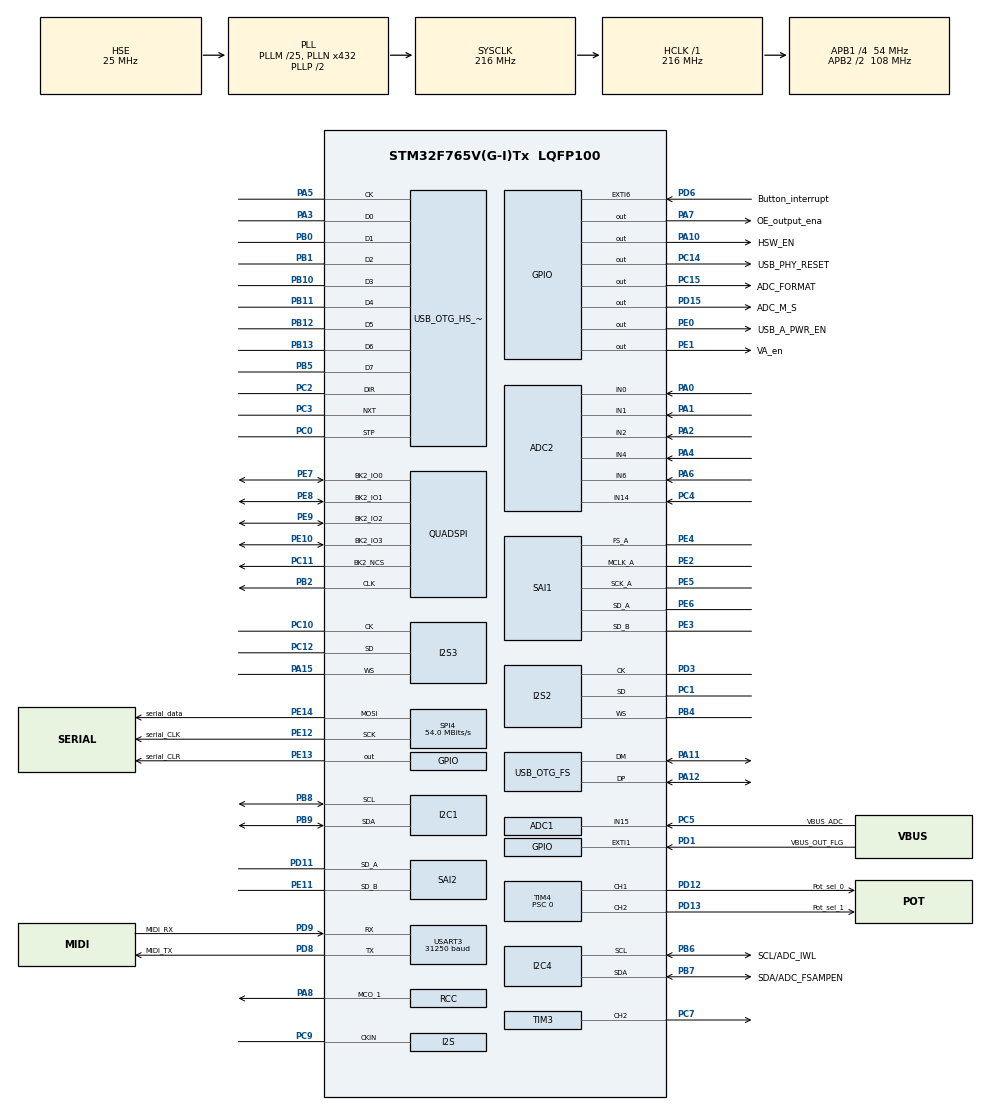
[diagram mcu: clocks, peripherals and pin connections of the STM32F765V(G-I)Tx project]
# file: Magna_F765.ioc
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ADC1.Channel-1\#ChannelRegularConversion=ADC_CHANNEL_TEMPSENSOR
ADC1.Channel-10\#ChannelRegularConversion=ADC_CHANNEL_15
ADC1.Channel-11\#ChannelRegularConversion=ADC_CHANNEL_15
ADC1.Channel-12\#ChannelRegularConversion=ADC_CHANNEL_15
ADC1.Channel-2\#ChannelRegularConversion=ADC_CHANNEL_TEMPSENSOR
ADC1.Channel-3\#ChannelRegularConversion=ADC_CHANNEL_TEMPSENSOR
ADC1.Channel-4\#ChannelRegularConversion=ADC_CHANNEL_TEMPSENSOR
ADC1.Channel-5\#ChannelRegularConversion=ADC_CHANNEL_VREFINT
ADC1.Channel-6\#ChannelRegularConversion=ADC_CHANNEL_VREFINT
ADC1.Channel-7\#ChannelRegularConversion=ADC_CHANNEL_VREFINT
ADC1.Channel-8\#ChannelRegularConversion=ADC_CHANNEL_VREFINT
ADC1.Channel-9\#ChannelRegularConversion=ADC_CHANNEL_15
ADC1.ContinuousConvMode=ENABLE
ADC1.DMAContinuousRequests=ENABLE
ADC1.EnableAnalogWatchDog=true
ADC1.ExternalTrigConv=ADC_EXTERNALTRIGCONV_T5_TRGO
ADC1.ITMode=ENABLE
ADC1.NbrOfConversion=12
ADC1.NbrOfConversionFlag=1
ADC1.Rank-1\#ChannelRegularConversion=1
ADC1.Rank-10\#ChannelRegularConversion=10
ADC1.Rank-11\#ChannelRegularConversion=11
ADC1.Rank-12\#ChannelRegularConversion=12
ADC1.Rank-2\#ChannelRegularConversion=2
ADC1.Rank-3\#ChannelRegularConversion=3
ADC1.Rank-4\#ChannelRegularConversion=4
ADC1.Rank-5\#ChannelRegularConversion=5
ADC1.Rank-6\#ChannelRegularConversion=6
ADC1.Rank-7\#ChannelRegularConversion=7
ADC1.Rank-8\#ChannelRegularConversion=8
ADC1.Rank-9\#ChannelRegularConversion=9
ADC1.SamplingTime-1\#ChannelRegularConversion=ADC_SAMPLETIME_480CYCLES
ADC1.SamplingTime-10\#ChannelRegularConversion=ADC_SAMPLETIME_480CYCLES
ADC1.SamplingTime-11\#ChannelRegularConversion=ADC_SAMPLETIME_480CYCLES
ADC1.SamplingTime-12\#ChannelRegularConversion=ADC_SAMPLETIME_480CYCLES
ADC1.SamplingTime-2\#ChannelRegularConversion=ADC_SAMPLETIME_480CYCLES
ADC1.SamplingTime-3\#ChannelRegularConversion=ADC_SAMPLETIME_480CYCLES
ADC1.SamplingTime-4\#ChannelRegularConversion=ADC_SAMPLETIME_480CYCLES
ADC1.SamplingTime-5\#ChannelRegularConversion=ADC_SAMPLETIME_480CYCLES
ADC1.SamplingTime-6\#ChannelRegularConversion=ADC_SAMPLETIME_480CYCLES
ADC1.SamplingTime-7\#ChannelRegularConversion=ADC_SAMPLETIME_480CYCLES
ADC1.SamplingTime-8\#ChannelRegularConversion=ADC_SAMPLETIME_480CYCLES
ADC1.SamplingTime-9\#ChannelRegularConversion=ADC_SAMPLETIME_480CYCLES
ADC1.WatchdogChannel=ADC_CHANNEL_15
ADC1.WatchdogMode=ADC_ANALOGWATCHDOG_SINGLE_REG
ADC1.master=1
ADC2.Channel-1\#ChannelRegularConversion=ADC_CHANNEL_0
ADC2.Channel-10\#ChannelRegularConversion=ADC_CHANNEL_6
ADC2.Channel-11\#ChannelRegularConversion=ADC_CHANNEL_14
ADC2.Channel-12\#ChannelRegularConversion=ADC_CHANNEL_14
ADC2.Channel-2\#ChannelRegularConversion=ADC_CHANNEL_0
ADC2.Channel-3\#ChannelRegularConversion=ADC_CHANNEL_1
ADC2.Channel-4\#ChannelRegularConversion=ADC_CHANNEL_1
ADC2.Channel-5\#ChannelRegularConversion=ADC_CHANNEL_2
ADC2.Channel-6\#ChannelRegularConversion=ADC_CHANNEL_2
ADC2.Channel-7\#ChannelRegularConversion=ADC_CHANNEL_4
ADC2.Channel-8\#ChannelRegularConversion=ADC_CHANNEL_4
ADC2.Channel-9\#ChannelRegularConversion=ADC_CHANNEL_6
ADC2.ClockPrescaler=ADC_CLOCK_SYNC_PCLK_DIV4
ADC2.ContinuousConvMode=ENABLE
ADC2.DMAContinuousRequests=ENABLE
ADC2.DiscontinuousConvMode=DISABLE
ADC2.EOCSelection=ADC_EOC_SINGLE_CONV
ADC2.ExternalTrigConv=ADC_EXTERNALTRIGCONV_T3_CC4
ADC2.ExternalTrigConvEdge=ADC_EXTERNALTRIGCONVEDGE_RISING
ADC2.InjNumberOfConversion=0
ADC2.NbrOfConversion=12
ADC2.NbrOfConversionFlag=1
ADC2.Rank-1\#ChannelRegularConversion=1
ADC2.Rank-10\#ChannelRegularConversion=10
ADC2.Rank-11\#ChannelRegularConversion=11
ADC2.Rank-12\#ChannelRegularConversion=12
ADC2.Rank-2\#ChannelRegularConversion=2
ADC2.Rank-3\#ChannelRegularConversion=3
ADC2.Rank-4\#ChannelRegularConversion=4
ADC2.Rank-5\#ChannelRegularConversion=5
ADC2.Rank-6\#ChannelRegularConversion=6
ADC2.Rank-7\#ChannelRegularConversion=7
ADC2.Rank-8\#ChannelRegularConversion=8
ADC2.Rank-9\#ChannelRegularConversion=9
ADC2.SamplingTime-1\#ChannelRegularConversion=ADC_SAMPLETIME_480CYCLES
ADC2.SamplingTime-10\#ChannelRegularConversion=ADC_SAMPLETIME_480CYCLES
ADC2.SamplingTime-11\#ChannelRegularConversion=ADC_SAMPLETIME_480CYCLES
ADC2.SamplingTime-12\#ChannelRegularConversion=ADC_SAMPLETIME_480CYCLES
ADC2.SamplingTime-2\#ChannelRegularConversion=ADC_SAMPLETIME_480CYCLES
ADC2.SamplingTime-3\#ChannelRegularConversion=ADC_SAMPLETIME_480CYCLES
ADC2.SamplingTime-4\#ChannelRegularConversion=ADC_SAMPLETIME_480CYCLES
ADC2.SamplingTime-5\#ChannelRegularConversion=ADC_SAMPLETIME_480CYCLES
ADC2.SamplingTime-6\#ChannelRegularConversion=ADC_SAMPLETIME_480CYCLES
ADC2.SamplingTime-7\#ChannelRegularConversion=ADC_SAMPLETIME_480CYCLES
ADC2.SamplingTime-8\#ChannelRegularConversion=ADC_SAMPLETIME_480CYCLES
ADC2.SamplingTime-9\#ChannelRegularConversion=ADC_SAMPLETIME_480CYCLES
ADC2.ScanConvMode=ADC_SCAN_ENABLE
CORTEX_M7.MPU_Control=__NULL
CORTEX_M7.default_mode_Activation=0
Dma.ADC1.6.Direction=DMA_PERIPH_TO_MEMORY
Dma.ADC1.6.FIFOMode=DMA_FIFOMODE_DISABLE
Dma.ADC1.6.Instance=DMA2_Stream4
Dma.ADC1.6.MemDataAlignment=DMA_MDATAALIGN_HALFWORD
Dma.ADC1.6.MemInc=DMA_MINC_ENABLE
Dma.ADC1.6.Mode=DMA_CIRCULAR
Dma.ADC1.6.PeriphDataAlignment=DMA_PDATAALIGN_HALFWORD
Dma.ADC1.6.PeriphInc=DMA_PINC_DISABLE
Dma.ADC1.6.Priority=DMA_PRIORITY_LOW
Dma.ADC2.7.Direction=DMA_PERIPH_TO_MEMORY
Dma.ADC2.7.FIFOMode=DMA_FIFOMODE_DISABLE
Dma.ADC2.7.Instance=DMA2_Stream3
Dma.ADC2.7.MemDataAlignment=DMA_MDATAALIGN_HALFWORD
Dma.ADC2.7.MemInc=DMA_MINC_ENABLE
Dma.ADC2.7.Mode=DMA_CIRCULAR
Dma.ADC2.7.PeriphDataAlignment=DMA_PDATAALIGN_HALFWORD
Dma.ADC2.7.PeriphInc=DMA_PINC_DISABLE
Dma.ADC2.7.Priority=DMA_PRIORITY_LOW
Dma.Request0=SAI1_A
Dma.Request1=SAI1_B
Dma.Request2=SPI2_TX
Dma.Request3=SPI3_TX
Dma.Request4=SAI2_A
Dma.Request5=SAI2_B
Dma.Request6=ADC1
Dma.Request7=ADC2
Dma.SAI1_A.0.Direction=DMA_PERIPH_TO_MEMORY
Dma.SAI1_A.0.FIFOMode=DMA_FIFOMODE_DISABLE
Dma.SAI1_A.0.Instance=DMA2_Stream1
Dma.SAI1_A.0.MemDataAlignment=DMA_MDATAALIGN_WORD
Dma.SAI1_A.0.MemInc=DMA_MINC_ENABLE
Dma.SAI1_A.0.Mode=DMA_CIRCULAR
Dma.SAI1_A.0.PeriphDataAlignment=DMA_PDATAALIGN_WORD
Dma.SAI1_A.0.PeriphInc=DMA_PINC_DISABLE
Dma.SAI1_A.0.Priority=DMA_PRIORITY_LOW
Dma.SAI1_B.1.Direction=DMA_PERIPH_TO_MEMORY
Dma.SAI1_B.1.FIFOMode=DMA_FIFOMODE_DISABLE
Dma.SAI1_B.1.Instance=DMA2_Stream0
Dma.SAI1_B.1.MemDataAlignment=DMA_MDATAALIGN_WORD
Dma.SAI1_B.1.MemInc=DMA_MINC_ENABLE
Dma.SAI1_B.1.Mode=DMA_CIRCULAR
Dma.SAI1_B.1.PeriphDataAlignment=DMA_PDATAALIGN_WORD
Dma.SAI1_B.1.PeriphInc=DMA_PINC_DISABLE
Dma.SAI1_B.1.Priority=DMA_PRIORITY_LOW
Dma.SAI2_A.4.Direction=DMA_PERIPH_TO_MEMORY
Dma.SAI2_A.4.FIFOMode=DMA_FIFOMODE_DISABLE
Dma.SAI2_A.4.Instance=DMA2_Stream2
Dma.SAI2_A.4.MemDataAlignment=DMA_MDATAALIGN_WORD
Dma.SAI2_A.4.MemInc=DMA_MINC_ENABLE
Dma.SAI2_A.4.Mode=DMA_CIRCULAR
Dma.SAI2_A.4.PeriphDataAlignment=DMA_PDATAALIGN_WORD
Dma.SAI2_A.4.PeriphInc=DMA_PINC_DISABLE
Dma.SAI2_A.4.Priority=DMA_PRIORITY_LOW
Dma.SAI2_B.5.Direction=DMA_PERIPH_TO_MEMORY
Dma.SAI2_B.5.FIFOMode=DMA_FIFOMODE_DISABLE
Dma.SAI2_B.5.Instance=DMA2_Stream6
Dma.SAI2_B.5.MemDataAlignment=DMA_MDATAALIGN_WORD
Dma.SAI2_B.5.MemInc=DMA_MINC_ENABLE
Dma.SAI2_B.5.Mode=DMA_CIRCULAR
Dma.SAI2_B.5.PeriphDataAlignment=DMA_PDATAALIGN_WORD
Dma.SAI2_B.5.PeriphInc=DMA_PINC_DISABLE
Dma.SAI2_B.5.Priority=DMA_PRIORITY_LOW
Dma.SPI2_TX.2.Direction=DMA_MEMORY_TO_PERIPH
Dma.SPI2_TX.2.FIFOMode=DMA_FIFOMODE_DISABLE
Dma.SPI2_TX.2.Instance=DMA1_Stream4
Dma.SPI2_TX.2.MemDataAlignment=DMA_MDATAALIGN_HALFWORD
Dma.SPI2_TX.2.MemInc=DMA_MINC_ENABLE
Dma.SPI2_TX.2.Mode=DMA_CIRCULAR
Dma.SPI2_TX.2.PeriphDataAlignment=DMA_PDATAALIGN_HALFWORD
Dma.SPI2_TX.2.PeriphInc=DMA_PINC_DISABLE
Dma.SPI2_TX.2.Priority=DMA_PRIORITY_LOW
Dma.SPI3_TX.3.Direction=DMA_MEMORY_TO_PERIPH
Dma.SPI3_TX.3.FIFOMode=DMA_FIFOMODE_DISABLE
Dma.SPI3_TX.3.Instance=DMA1_Stream5
Dma.SPI3_TX.3.MemDataAlignment=DMA_MDATAALIGN_HALFWORD
Dma.SPI3_TX.3.MemInc=DMA_MINC_ENABLE
Dma.SPI3_TX.3.Mode=DMA_CIRCULAR
Dma.SPI3_TX.3.PeriphDataAlignment=DMA_PDATAALIGN_HALFWORD
Dma.SPI3_TX.3.PeriphInc=DMA_PINC_DISABLE
Dma.SPI3_TX.3.Priority=DMA_PRIORITY_LOW
I2C1.Timing=0x20404768
I2C4.Timing=0x20404768
I2S2.AudioFreq=I2S_AUDIOFREQ_48K
I2S2.CPOL=I2S_CPOL_HIGH
I2S2.DataFormat=I2S_DATAFORMAT_32B
I2S2.ErrorAudioFreq=0.0 %
I2S2.FullDuplexMode=I2S_FULLDUPLEXMODE_DISABLE
I2S2.Instance=SPI$Index
I2S2.Mode=I2S_MODE_SLAVE_TX
I2S2.RealAudioFreq=48.0 KHz
I2S2.Standard=I2S_STANDARD_PHILIPS
I2S2.VirtualMode=I2S_MODE_SLAVE
I2S3.AudioFreq=I2S_AUDIOFREQ_48K
I2S3.CPOL=I2S_CPOL_HIGH
I2S3.DataFormat=I2S_DATAFORMAT_32B
I2S3.ErrorAudioFreq=0.0 %
I2S3.FullDuplexMode=I2S_FULLDUPLEXMODE_DISABLE
I2S3.Instance=SPI$Index
I2S3.Mode=I2S_MODE_SLAVE_TX
I2S3.RealAudioFreq=48.0 KHz
I2S3.Standard=I2S_STANDARD_PHILIPS
I2S3.VirtualMode=I2S_MODE_SLAVE
Mcu.Family=STM32F7
Mcu.Name=STM32F765V(G-I)Tx
Mcu.Package=LQFP100
NVIC.ADC_IRQn=true\:0\:0\:false\:false\:true\:false\:true\:true\:true
NVIC.DMA1_Stream4_IRQn=true\:5\:0\:true\:false\:true\:true\:false\:true\:true
NVIC.DMA1_Stream5_IRQn=true\:5\:0\:true\:false\:true\:true\:false\:true\:true
NVIC.DMA2_Stream0_IRQn=true\:5\:0\:true\:false\:true\:true\:false\:true\:true
NVIC.DMA2_Stream1_IRQn=true\:5\:0\:true\:false\:true\:true\:false\:true\:true
NVIC.DMA2_Stream2_IRQn=true\:5\:0\:true\:false\:true\:true\:false\:true\:true
NVIC.DMA2_Stream3_IRQn=true\:0\:0\:false\:false\:true\:true\:false\:true\:true
NVIC.DMA2_Stream4_IRQn=true\:0\:0\:false\:false\:true\:true\:false\:true\:true
NVIC.DMA2_Stream6_IRQn=true\:5\:0\:true\:false\:true\:true\:false\:true\:true
NVIC.PriorityGroup=NVIC_PRIORITYGROUP_4
NVIC.SAI1_IRQn=true\:4\:0\:true\:false\:true\:false\:true\:true\:true
NVIC.SAI2_IRQn=true\:4\:0\:true\:false\:true\:false\:true\:true\:true
NVIC.SPI2_IRQn=true\:5\:0\:true\:false\:true\:false\:true\:true\:true
NVIC.SPI3_IRQn=true\:14\:0\:true\:false\:true\:false\:true\:true\:true
NVIC.TIM6_DAC_IRQn=true\:15\:0\:false\:false\:true\:false\:false\:true\:true
NVIC.TIM8_TRG_COM_TIM14_IRQn=true\:14\:0\:true\:false\:true\:false\:true\:true\:true
NVIC.TimeBase=TIM6_DAC_IRQn
NVIC.TimeBaseIP=TIM6
PA0/WKUP.Signal=ADCx_IN0
PA1.Signal=ADCx_IN1
PA10.GPIO_Label=HSW_EN
PA10.Signal=GPIO_Output
PA11.Mode=Host_Only
PA11.Signal=USB_OTG_FS_DM
PA12.Mode=Host_Only
PA12.Signal=USB_OTG_FS_DP
PA13.Mode=Trace_Asynchronous_SW
PA13.Signal=SYS_JTMS-SWDIO
PA14.Mode=Trace_Asynchronous_SW
PA14.Signal=SYS_JTCK-SWCLK
PA15.Mode=Half_Duplex_Slave
PA15.Signal=I2S3_WS
PA2.Signal=ADCx_IN2
PA3.Mode=OTG/Dual-Role-Device-HS
PA3.Signal=USB_OTG_HS_ULPI_D0
PA4.Signal=ADCx_IN4
PA5.Mode=OTG/Dual-Role-Device-HS
PA5.Signal=USB_OTG_HS_ULPI_CK
PA6.Signal=ADCx_IN6
PA7.GPIO_Label=OE_output_ena
PA7.GPIO_Speed=GPIO_SPEED_FREQ_MEDIUM
PA7.PinState=GPIO_PIN_RESET
PA7.Signal=GPIO_Output
PA8.Mode=Clock-out-1
PA8.Signal=RCC_MCO_1
PB0.Mode=OTG/Dual-Role-Device-HS
PB0.Signal=USB_OTG_HS_ULPI_D1
PB1.Mode=OTG/Dual-Role-Device-HS
PB1.Signal=USB_OTG_HS_ULPI_D2
PB10.Mode=OTG/Dual-Role-Device-HS
PB10.Signal=USB_OTG_HS_ULPI_D3
PB11.Mode=OTG/Dual-Role-Device-HS
PB11.Signal=USB_OTG_HS_ULPI_D4
PB12.Mode=OTG/Dual-Role-Device-HS
PB12.Signal=USB_OTG_HS_ULPI_D5
PB13.Mode=OTG/Dual-Role-Device-HS
PB13.Signal=USB_OTG_HS_ULPI_D6
PB14.Signal=USB_OTG_HS_DM
PB15.Signal=USB_OTG_HS_DP
PB2.Mode=Single Bank 2
PB2.Signal=QUADSPI_CLK
PB3.Mode=Trace_Asynchronous_SW
PB3.Signal=SYS_JTDO-SWO
PB4.GPIO_Speed=GPIO_SPEED_FREQ_VERY_HIGH
PB4.Mode=Half_Duplex_Slave
PB4.Signal=I2S2_WS
PB5.Mode=OTG/Dual-Role-Device-HS
PB5.Signal=USB_OTG_HS_ULPI_D7
PB6.GPIO_Label=SCL/ADC_IWL
PB6.Mode=I2C
PB6.Signal=I2C4_SCL
PB7.GPIO_Label=SDA/ADC_FSAMPEN
PB7.Mode=I2C
PB7.Signal=I2C4_SDA
PB8.Mode=I2C
PB8.Signal=I2C1_SCL
PB9.Mode=I2C
PB9.Signal=I2C1_SDA
PC0.Mode=OTG/Dual-Role-Device-HS
PC0.Signal=USB_OTG_HS_ULPI_STP
PC1.GPIO_Speed=GPIO_SPEED_FREQ_VERY_HIGH
PC1.Mode=Half_Duplex_Slave
PC1.Signal=I2S2_SD
PC10.Mode=Half_Duplex_Slave
PC10.Signal=I2S3_CK
PC11.Mode=Single Bank 2
PC11.Signal=QUADSPI_BK2_NCS
PC12.GPIO_Speed=GPIO_SPEED_FREQ_VERY_HIGH
PC12.Mode=Half_Duplex_Slave
PC12.Signal=I2S3_SD
PC14/OSC32_IN.GPIO_Label=USB_PHY_RESET
PC14/OSC32_IN.Signal=GPIO_Output
PC15/OSC32_OUT.GPIO_Label=ADC_FORMAT
PC15/OSC32_OUT.Signal=GPIO_Output
PC2.Mode=OTG/Dual-Role-Device-HS
PC2.Signal=USB_OTG_HS_ULPI_DIR
PC3.Mode=OTG/Dual-Role-Device-HS
PC3.Signal=USB_OTG_HS_ULPI_NXT
PC4.Signal=ADCx_IN14
PC5.GPIO_Label=VBUS_ADC
PC5.Signal=ADCx_IN15
PC7.Signal=S_TIM3_CH2
PC9.Mode=Audio_ClockIn
PC9.Signal=I2S_CKIN
PD1.GPIO_Label=VBUS_OUT_FLG
PD1.Signal=GPXTI1
PD11.Mode=SAI_A_SyncSlave
PD11.Signal=SAI2_SD_A
PD12.GPIO_Label=Pot_sel_0
PD12.Signal=S_TIM4_CH1
PD13.GPIO_Label=Pot_sel_1
PD13.Signal=S_TIM4_CH2
PD15.GPIO_Label=ADC_M_S
PD15.Signal=GPIO_Output
PD3.GPIO_Speed=GPIO_SPEED_FREQ_VERY_HIGH
PD3.Mode=Half_Duplex_Slave
PD3.Signal=I2S2_CK
PD6.GPIO_Label=Button_interrupt
PD6.Signal=GPXTI6
PD8.GPIO_Label=MIDI_TX
PD8.Mode=Asynchronous
PD8.Signal=USART3_TX
PD9.GPIO_Label=MIDI_RX
PD9.Mode=Asynchronous
PD9.Signal=USART3_RX
PE0.GPIO_Label=USB_A_PWR_EN
PE0.Signal=GPIO_Output
PE1.GPIO_Label=VA_en
PE1.Signal=GPIO_Output
PE10.Mode=Single Bank 2
PE10.Signal=QUADSPI_BK2_IO3
PE11.Mode=SAI_B_SyncSlave
PE11.Signal=SAI2_SD_B
PE12.GPIO_Label=serial_CLK
PE12.Mode=TX_Only_Simplex_Unidirect_Master
PE12.Signal=SPI4_SCK
PE13.GPIO_Label=serial_CLR
PE13.Signal=GPIO_Output
PE14.GPIO_Label=serial_data
PE14.Mode=TX_Only_Simplex_Unidirect_Master
PE14.Signal=SPI4_MOSI
PE2.Mode=SAI_A_MasterWithClock
PE2.Signal=SAI1_MCLK_A
PE3.GPIO_Speed=GPIO_SPEED_FREQ_VERY_HIGH
PE3.Mode=SAI_B_SyncSlave
PE3.Signal=SAI1_SD_B
PE4.GPIO_Speed=GPIO_SPEED_FREQ_VERY_HIGH
PE4.Mode=SAI_A_MasterWithClock
PE4.Signal=SAI1_FS_A
PE5.GPIO_Speed=GPIO_SPEED_FREQ_VERY_HIGH
PE5.Mode=SAI_A_MasterWithClock
PE5.Signal=SAI1_SCK_A
PE6.GPIO_Speed=GPIO_SPEED_FREQ_VERY_HIGH
PE6.Mode=SAI_A_MasterWithClock
PE6.Signal=SAI1_SD_A
PE7.Mode=Single Bank 2
PE7.Signal=QUADSPI_BK2_IO0
PE8.Mode=Single Bank 2
PE8.Signal=QUADSPI_BK2_IO1
PE9.Mode=Single Bank 2
PE9.Signal=QUADSPI_BK2_IO2
PH0/OSC_IN.Mode=HSE-External-Oscillator
PH0/OSC_IN.Signal=RCC_OSC_IN
PH1/OSC_OUT.Mode=HSE-External-Oscillator
PH1/OSC_OUT.Signal=RCC_OSC_OUT
ProjectManager.HeapSize=0x000
ProjectManager.StackSize=0x400
ProjectManager.TargetToolchain=Makefile
QUADSPI.ClockPrescaler=0
RCC.AHBFreq_Value=216000000
RCC.APB1CLKDivider=RCC_HCLK_DIV4
RCC.APB1Freq_Value=54000000
RCC.APB1TimFreq_Value=108000000
RCC.APB2CLKDivider=RCC_HCLK_DIV2
RCC.APB2Freq_Value=108000000
RCC.APB2TimFreq_Value=216000000
RCC.CortexFreq_Value=216000000
RCC.EXTERNAL_CLOCK_VALUE=24576000
RCC.HCLKFreq_Value=216000000
RCC.HSE_VALUE=25000000
RCC.HSI_VALUE=16000000
RCC.I2SCLockSelection=RCC_I2SCLKSOURCE_EXT
RCC.LSE_VALUE=32768
RCC.PLL48CLockSelection=RCC_CLK48SOURCE_PLLSAIP
RCC.PLLI2SN=432
RCC.PLLM=25
RCC.PLLN=432
RCC.PLLQ=10
RCC.PLLSAIP=RCC_PLLSAIP_DIV4
RCC.PLLSAIQ=4
RCC.RCC_MCO1Source=RCC_MCO1SOURCE_PLLCLK
RCC.SAI1CLockSelection=RCC_SAI1CLKSOURCE_PIN
RCC.SAI2CLockSelection=RCC_SAI2CLKSOURCE_PIN
RCC.SYSCLKFreq_VALUE=216000000
RCC.SYSCLKSource=RCC_SYSCLKSOURCE_PLLCLK
RCC.USBFreq_Value=48000000
RCC.VCOOutputFreq_Value=432000000
SAI1.AudioFrequency-SAI_A_MasterWithClock=SAI_AUDIO_FREQUENCY_48K
SAI1.AudioMode-SAI_A_MasterWithClock=SAI_MODEMASTER_RX
SAI1.BasicDataSize-SAI_A_MasterWithClock=SAI_PROTOCOL_DATASIZE_32BIT
SAI1.BasicDataSize-SAI_B_SyncSlave=SAI_PROTOCOL_DATASIZE_32BIT
SAI1.ErrorAudioFreq-SAI_A_MasterWithClock=0.0 %
SAI1.InitProtocol-SAI_A_MasterWithClock=Enable
SAI1.InitProtocol-SAI_B_SyncSlave=Enable
SAI1.Instance-SAI_A_MasterWithClock=SAI$Index_Block_A
SAI1.Instance-SAI_B_SyncSlave=SAI$Index_Block_B
SAI1.MClockEnable=SAI_MASTERCLOCK_ENABLE
SAI1.RealAudioFreq-SAI_A_MasterWithClock=48.0 KHz
SAI1.SynchroExt=SAI_SYNCEXT_OUTBLOCKA_ENABLE
SAI1.VirtualMode-SAI_A_MasterWithClock=VM_MASTER
SAI1.VirtualMode-SAI_B_SyncSlave=VM_SLAVE
SAI1.VirtualProtocol-SAI_A_BASIC=VM_BASIC_PROTOCOL
SAI1.VirtualProtocol-SAI_B_BASIC=VM_BASIC_PROTOCOL
SAI2.BasicDataSize-SAI_A_SyncSlave=SAI_PROTOCOL_DATASIZE_32BIT
SAI2.BasicDataSize-SAI_B_SyncSlave=SAI_PROTOCOL_DATASIZE_32BIT
SAI2.InitProtocol-SAI_A_SyncSlave=Enable
SAI2.InitProtocol-SAI_B_SyncSlave=Enable
SAI2.Instance-SAI_A_SyncSlave=SAI$Index_Block_A
SAI2.Instance-SAI_B_SyncSlave=SAI$Index_Block_B
SAI2.Synchro_A=SAI_SYNCHRONOUS_EXT_SAI1
SAI2.Synchro_B=SAI_SYNCHRONOUS_EXT_SAI1
SAI2.VirtualMode-SAI_A_SyncSlave=VM_SLAVE
SAI2.VirtualMode-SAI_B_SyncSlave=VM_SLAVE
SAI2.VirtualProtocol-SAI_A_BASIC=VM_BASIC_PROTOCOL
SAI2.VirtualProtocol-SAI_B_BASIC=VM_BASIC_PROTOCOL
SH.ADCx_IN0.0=ADC2_IN0,IN0
SH.ADCx_IN1.0=ADC2_IN1,IN1
SH.ADCx_IN14.0=ADC2_IN14,IN14
SH.ADCx_IN15.0=ADC1_IN15,IN15
SH.ADCx_IN2.0=ADC2_IN2,IN2
SH.ADCx_IN4.0=ADC2_IN4,IN4
SH.ADCx_IN6.0=ADC2_IN6,IN6
SH.S_TIM3_CH2.0=TIM3_CH2,Output Compare2 CH2
SH.S_TIM4_CH1.0=TIM4_CH1,Output Compare1 CH1
SH.S_TIM4_CH2.0=TIM4_CH2,Output Compare2 CH2
SPI4.BaudRatePrescaler=SPI_BAUDRATEPRESCALER_2
SPI4.CalculateBaudRate=54.0 MBits/s
SPI4.Direction=SPI_DIRECTION_2LINES
SPI4.Mode=SPI_MODE_MASTER
SPI4.VirtualType=VM_MASTER
STMicroelectronics.X-CUBE-AZRTOS-F7.1.1.0.FileXCcFileOoSystemJjFileXJjCore=true
STMicroelectronics.X-CUBE-AZRTOS-F7.1.1.0.FileXCcFileOoSystemJjFileXJjTraceXOoSupport=true
STMicroelectronics.X-CUBE-AZRTOS-F7.1.1.0.TX_BLOCK_POOL_ENABLE_PERFORMANCE_INFO=0
STMicroelectronics.X-CUBE-AZRTOS-F7.1.1.0.TX_ENABLE_EVENT_TRACE=1
STMicroelectronics.X-CUBE-AZRTOS-F7.1.1.0.TX_LOW_POWER=0
STMicroelectronics.X-CUBE-AZRTOS-F7.1.1.0.TX_NOT_INTERRUPTABLE=0
STMicroelectronics.X-CUBE-AZRTOS-F7.1.1.0.TX_TIMER_TICKS_PER_SECOND=1000
STMicroelectronics.X-CUBE-AZRTOS-F7.1.1.0.ThreadXCcRTOSJjThreadXJjCore=true
STMicroelectronics.X-CUBE-AZRTOS-F7.1.1.0.ThreadXCcRTOSJjThreadXJjLowOoPowerOosupport=true
STMicroelectronics.X-CUBE-AZRTOS-F7.1.1.0.ThreadXCcRTOSJjThreadXJjPerformanceInfo=true
STMicroelectronics.X-CUBE-AZRTOS-F7.1.1.0.ThreadXCcRTOSJjThreadXJjTraceXOosupport=true
STMicroelectronics.X-CUBE-AZRTOS-F7.1.1.0.USBXCcUSBJjUSBXJjCoreSystem=true
STMicroelectronics.X-CUBE-AZRTOS-F7.1.1.0.USBXCcUSBJjUSBXJjTraceXOoSupport=true
STMicroelectronics.X-CUBE-AZRTOS-F7.1.1.0.USBXCcUSBJjUSBXJjUXOoDeviceOoClassOoAUDIO=true
STMicroelectronics.X-CUBE-AZRTOS-F7.1.1.0.USBXCcUSBJjUSBXJjUXOoDeviceOoClassOoSTORAGE=true
STMicroelectronics.X-CUBE-AZRTOS-F7.1.1.0.USBXCcUSBJjUSBXJjUXOoDeviceOoCoreStack=true
STMicroelectronics.X-CUBE-AZRTOS-F7.1.1.0.USBXCcUSBJjUSBXJjUXOoHostOoClassOoAUDIO=true
STMicroelectronics.X-CUBE-AZRTOS-F7.1.1.0.USBXCcUSBJjUSBXJjUXOoHostOoClassOoSTORAGE=true
STMicroelectronics.X-CUBE-AZRTOS-F7.1.1.0.USBXCcUSBJjUSBXJjUXOoHostOoCoreStack=true
STMicroelectronics.X-CUBE-AZRTOS-F7.1.1.0.UX_OTG_SUPPORT=1
STMicroelectronics.X-CUBE-AZRTOS-F7.1.1.0.UX_PERIODIC_RATE=10000
STMicroelectronics.X-CUBE-AZRTOS-F7.1.1.0_IsAnAzureRtosMw=true
TIM3.AutoReloadPreload=TIM_AUTORELOAD_PRELOAD_ENABLE
TIM3.Channel-Output\ Compare2\ CH2=TIM_CHANNEL_2
TIM3.Channel-Output\ Compare4\ No\ Output=TIM_CHANNEL_4
TIM3.ClockDivision=TIM_CLOCKDIVISION_DIV1
TIM3.OCMode_2=TIM_OCMODE_TOGGLE
TIM3.OCMode_4=TIM_OCMODE_TOGGLE
TIM3.OCPolarity_2=TIM_OCPOLARITY_HIGH
TIM3.OCPolarity_4=TIM_OCPOLARITY_HIGH
TIM3.Period=49
TIM3.Prescaler=1340
TIM3.Pulse-Output\ Compare2\ CH2=2
TIM3.Pulse-Output\ Compare4\ No\ Output=2
TIM3.TIM_MasterOutputTrigger=TIM_TRGO_OC1
TIM3.TIM_MasterSlaveMode=TIM_MASTERSLAVEMODE_DISABLE
TIM4.AutoReloadPreload=TIM_AUTORELOAD_PRELOAD_ENABLE
TIM4.Channel-Output\ Compare1\ CH1=TIM_CHANNEL_1
TIM4.Channel-Output\ Compare2\ CH2=TIM_CHANNEL_2
TIM4.OC1Preload=ENABLE
TIM4.OC2Preload=ENABLE
TIM4.OCMode_1=TIM_OCMODE_TOGGLE
TIM4.OCMode_2=TIM_OCMODE_TOGGLE
TIM4.OCPolarity_1=TIM_OCPOLARITY_HIGH
TIM4.OCPolarity_2=TIM_OCPOLARITY_HIGH
TIM4.Period=3
TIM4.Prescaler=0
TIM4.Pulse-Output\ Compare1\ CH1=2
TIM4.Pulse-Output\ Compare2\ CH2=0
TIM4.TIM_MasterSlaveMode=TIM_MASTERSLAVEMODE_DISABLE
TIM5.Channel-Output\ Compare1\ No\ Output=TIM_CHANNEL_1
TIM5.OCMode_1=TIM_OCMODE_TOGGLE
TIM5.Period=2000
TIM5.Prescaler=2160
TIM5.TIM_MasterOutputTrigger=TIM_TRGO_OC1REF
USART3.BaudRate=31250
USART3.VirtualMode-Asynchronous=VM_ASYNC
USB_OTG_FS.VirtualMode=Host_Only
USB_OTG_FS.phy_itface=HCD_PHY_EMBEDDED
VP_ADC1_TempSens_Input.Mode=IN-TempSens
VP_ADC1_Vref_Input.Mode=IN-Vrefint
VP_SAI1_VP_$IpInstance_SAIA_SAI_BASIC.Mode=SAI_A_BASIC
VP_SAI1_VP_$IpInstance_SAIB_SAI_BASIC.Mode=SAI_B_BASIC
VP_SAI1_VP_$IpInstance_SYNCHRO_EXTERNAL.Mode=SynchroExternal
VP_SAI2_VP_$IpInstance_SAIA_SAI_BASIC.Mode=SAI_A_BASIC
VP_SAI2_VP_$IpInstance_SAIB_SAI_BASIC.Mode=SAI_B_BASIC
VP_STMicroelectronics.X-CUBE-AZRTOS-F7_VS_FileOoSystemJjFileX_6.1.10_1.1.0.Mode=FileOoSystemJjFileX
VP_STMicroelectronics.X-CUBE-AZRTOS-F7_VS_RTOSJjThreadX_6.1.10_1.1.0.Mode=RTOSJjThreadX
VP_STMicroelectronics.X-CUBE-AZRTOS-F7_VS_USBJjUSBX_6.1.10_1.1.0.Mode=USBJjUSBX
VP_SYS_VS_tim6.Mode=TIM6
VP_TIM14_VS_ClockSourceINT.Mode=Enable_Timer
VP_TIM3_VS_ClockSourceINT.Mode=Internal
VP_TIM3_VS_no_output4.Mode=Output Compare4 No Output
VP_TIM4_VS_ClockSourceITR.Mode=TriggerSource_ITR2
VP_TIM4_VS_ControllerModeClock.Mode=Clock Mode
VP_TIM5_VS_ClockSourceINT.Mode=Internal
VP_TIM5_VS_no_output1.Mode=Output Compare1 No Output
board=custom

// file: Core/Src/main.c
/* USER CODE BEGIN Header */
/**
  ******************************************************************************
  * @file           : main.c
  * @brief          : Main program body
  ******************************************************************************
  * @attention
  *
  * Copyright (c) 2025 STMicroelectronics.
  * All rights reserved.
  *
  * This software is licensed under terms that can be found in the LICENSE file
  * in the root directory of this software component.
  * If no LICENSE file comes with this software, it is provided AS-IS.
  *
  ******************************************************************************
  */
/* USER CODE END Header */
#include "app_threadx.h"
#include "main.h"
#include "adc.h"
#include "dma.h"
#include "i2c.h"
#include "i2s.h"
#include "quadspi.h"
#include "sai.h"
#include "spi.h"
#include "tim.h"
#include "usart.h"
#include "usb_otg.h"
#include "gpio.h"

/* USER CODE BEGIN Includes */
#include "SEGGER_RTT.h"
/* USER CODE END Includes */

/* USER CODE BEGIN PV */
char main_diagbuffer[100];
/* USER CODE END PV */

void SystemClock_Config(void);

int main(void)
{

  /* MCU Configuration--------------------------------------------------------*/

  /* Reset of all peripherals, Initializes the Flash interface and the Systick. */
  HAL_Init();

  /* Configure the system clock */
  SystemClock_Config();

  /* Initialize all configured peripherals */
  MX_GPIO_Init();
  MX_DMA_Init();
  MX_ADC1_Init();
  MX_ADC2_Init();
  MX_I2C1_Init();
  MX_I2S2_Init();
  MX_I2S3_Init();
  MX_QUADSPI_Init();
  MX_SAI1_Init();
  MX_SAI2_Init();
  MX_SPI4_Init();
  MX_TIM4_Init();
  MX_USB_OTG_FS_HCD_Init();
  MX_USB_OTG_HS_USB_Init();
  MX_USART3_UART_Init();
  MX_I2C4_Init();
  MX_TIM14_Init();
  MX_TIM3_Init();
  MX_TIM5_Init();
  /* USER CODE BEGIN 2 */
  SEGGER_RTT_WriteString(0, "Init complete\r\n");

  /* USER CODE END 2 */

  MX_ThreadX_Init();

  /* We should never get here as control is now taken by the scheduler */

  /* Infinite loop */
  while (1)
  {

  }
}

void SystemClock_Config(void)
{
  RCC_OscInitTypeDef RCC_OscInitStruct = {0};
  RCC_ClkInitTypeDef RCC_ClkInitStruct = {0};

  /** Configure the main internal regulator output voltage
  */
  __HAL_RCC_PWR_CLK_ENABLE();
  __HAL_PWR_VOLTAGESCALING_CONFIG(PWR_REGULATOR_VOLTAGE_SCALE1);

  /** Initializes the RCC Oscillators according to the specified parameters
  * in the RCC_OscInitTypeDef structure.
  */
  RCC_OscInitStruct.OscillatorType = RCC_OSCILLATORTYPE_HSE;
  RCC_OscInitStruct.HSEState = RCC_HSE_ON;
  RCC_OscInitStruct.PLL.PLLState = RCC_PLL_ON;
  RCC_OscInitStruct.PLL.PLLSource = RCC_PLLSOURCE_HSE;
  RCC_OscInitStruct.PLL.PLLM = 25;
  RCC_OscInitStruct.PLL.PLLN = 432;
  RCC_OscInitStruct.PLL.PLLP = RCC_PLLP_DIV2;
  RCC_OscInitStruct.PLL.PLLQ = 10;
  RCC_OscInitStruct.PLL.PLLR = 2;
  if (HAL_RCC_OscConfig(&RCC_OscInitStruct) != HAL_OK)
  {
    Error_Handler();
  }

  /** Activate the Over-Drive mode
  */
  if (HAL_PWREx_EnableOverDrive() != HAL_OK)
  {
    Error_Handler();
  }

  /** Initializes the CPU, AHB and APB buses clocks
  */
  RCC_ClkInitStruct.ClockType = RCC_CLOCKTYPE_HCLK|RCC_CLOCKTYPE_SYSCLK
                              |RCC_CLOCKTYPE_PCLK1|RCC_CLOCKTYPE_PCLK2;
  RCC_ClkInitStruct.SYSCLKSource = RCC_SYSCLKSOURCE_PLLCLK;
  RCC_ClkInitStruct.AHBCLKDivider = RCC_SYSCLK_DIV1;
  RCC_ClkInitStruct.APB1CLKDivider = RCC_HCLK_DIV4;
  RCC_ClkInitStruct.APB2CLKDivider = RCC_HCLK_DIV2;

  if (HAL_RCC_ClockConfig(&RCC_ClkInitStruct, FLASH_LATENCY_7) != HAL_OK)
  {
    Error_Handler();
  }
  HAL_RCC_MCOConfig(RCC_MCO1, RCC_MCO1SOURCE_PLLCLK, RCC_MCODIV_1);
}

void HAL_TIM_PeriodElapsedCallback(TIM_HandleTypeDef *htim)
{
  if (htim->Instance == TIM6)
  {
    HAL_IncTick();
  }
  /* USER CODE BEGIN Callback 1 */
  else if (htim->Instance == TIM14) {
    HAL_TIM_Base_Stop_IT(htim);
    SEGGER_RTT_WriteString (0, main_diagbuffer);
    HAL_GPIO_WritePin(OE_output_ena_GPIO_Port, OE_output_ena_Pin, GPIO_PIN_RESET);
    validate_dma_completion();
  }
  /* USER CODE END Callback 1 */
}

void Error_Handler(void)
{
  /* USER CODE BEGIN Error_Handler_Debug */
  /* User can add his own implementation to report the HAL error return state */
  __disable_irq();
  __BKPT();
  while (1)
  {
  }
  /* USER CODE END Error_Handler_Debug */
}
